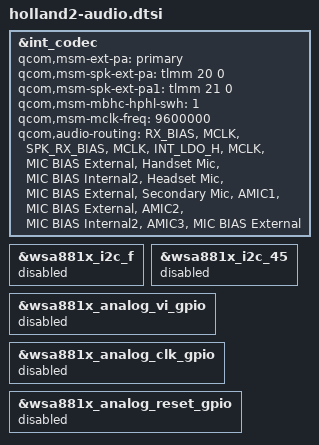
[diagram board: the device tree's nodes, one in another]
/* Copyright (c) 2020, The Linux Foundation. All rights reserved.
*  Copyright (c) 2020, Jebaitedneko.
*
* This program is free software; you can redistribute it and/or modify
* it under the terms of the GNU General Public License version 2 and
* only version 2 as published by the Free Software Foundation.
*
* This program is distributed in the hope that it will be useful,
* but WITHOUT ANY WARRANTY; without even the implied warranty of
* MERCHANTABILITY or FITNESS FOR A PARTICULAR PURPOSE.  See the
* GNU General Public License for more details.
*/

&int_codec {

	status = "okay";

	qcom,msm-ext-pa = "primary";
	qcom,msm-spk-ext-pa = <&tlmm 20 0>;
	qcom,msm-spk-ext-pa1 = <&tlmm 21 0>;
	qcom,msm-mbhc-hphl-swh = <1>;
	qcom,msm-mclk-freq = <9600000>;
	qcom,audio-routing =
			"RX_BIAS", "MCLK",
			"SPK_RX_BIAS", "MCLK",
			"INT_LDO_H", "MCLK",
			"MIC BIAS External", "Handset Mic",
			"MIC BIAS Internal2", "Headset Mic",
			"MIC BIAS External", "Secondary Mic",
			"AMIC1", "MIC BIAS External",
			"AMIC2", "MIC BIAS Internal2",
			"AMIC3", "MIC BIAS External";

	/delete-property/ asoc-wsa-codec-names;
	/delete-property/ asoc-wsa-codec-prefixes;
	/delete-property/ msm-vdd-wsa-switch-supply;
	/delete-property/ qcom,cdc-us-euro-gpios;
	/delete-property/ qcom,msm-vdd-wsa-switch-current;
	/delete-property/ qcom,msm-vdd-wsa-switch-voltage;

};

&wsa881x_i2c_f {
        status = "disabled";
};

&wsa881x_i2c_45 {
        status = "disabled";
};

&wsa881x_analog_vi_gpio {
        status = "disabled";
};

&wsa881x_analog_clk_gpio {
        status = "disabled";
};

&wsa881x_analog_reset_gpio {
        status = "disabled";
};
